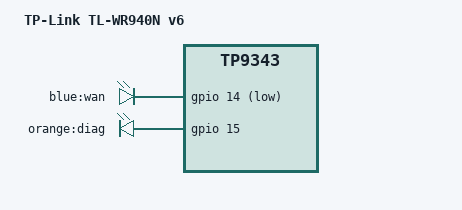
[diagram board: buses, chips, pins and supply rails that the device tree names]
// SPDX-License-Identifier: GPL-2.0-or-later OR MIT

#include "tp9343_tplink_tl-wr94x.dtsi"

/ {
	compatible = "tplink,tl-wr940n-v6", "qca,tp9343";
	model = "TP-Link TL-WR940N v6";

	aliases {
		led-boot = &led_diag_orange;
		led-failsafe = &led_diag_orange;
		led-running = &led_diag_orange;
		led-upgrade = &led_diag_orange;
	};

	leds {
		compatible = "gpio-leds";

		wan_blue {
			label = "blue:wan";
			gpios = <&gpio 14 GPIO_ACTIVE_LOW>;
		};

		led_diag_orange: diag_orange {
			label = "orange:diag";
			gpios = <&gpio 15 GPIO_ACTIVE_HIGH>;
			default-state = "on";
		};
	};
};

&eth1 {
	nvmem-cells = <&macaddr_uboot_1fc00>;
	nvmem-cell-names = "mac-address";
};
